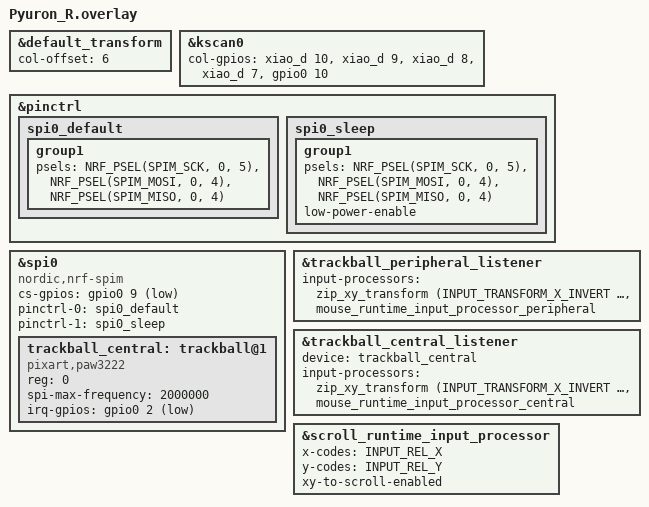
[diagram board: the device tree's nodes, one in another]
#include "Pyuron.dtsi"
#include <zephyr/dt-bindings/input/input-event-codes.h>
#include <dt-bindings/zmk/input_transform.h>
#include <input/processors.dtsi>
#include <input/processors/runtime-input-processor.dtsi>
#include <dt-bindings/zmk/bt.h>

&default_transform {
    col-offset = <6>;
};

&kscan0 {
    col-gpios = <&xiao_d 10 GPIO_ACTIVE_HIGH>,
                <&xiao_d 9 GPIO_ACTIVE_HIGH>,
                <&xiao_d 8 GPIO_ACTIVE_HIGH>,
                <&xiao_d 7 GPIO_ACTIVE_HIGH>,
                <&gpio0 10 GPIO_ACTIVE_HIGH>;
};

&pinctrl {
    spi0_default: spi0_default {
        group1 {
            psels = <NRF_PSEL(SPIM_SCK, 0, 5)>,
                    <NRF_PSEL(SPIM_MOSI, 0, 4)>,
                    <NRF_PSEL(SPIM_MISO, 0, 4)>;
        };
    };

    spi0_sleep: spi0_sleep {
        group1 {
            psels = <NRF_PSEL(SPIM_SCK, 0, 5)>,
                    <NRF_PSEL(SPIM_MOSI, 0, 4)>,
                    <NRF_PSEL(SPIM_MISO, 0, 4)>;
            low-power-enable;
        };
    };
};

&spi0 {
    status = "okay";
    cs-gpios = <&gpio0 9 GPIO_ACTIVE_LOW>;
    pinctrl-0 = <&spi0_default>;
    pinctrl-1 = <&spi0_sleep>;
    pinctrl-names = "default", "sleep";
    compatible = "nordic,nrf-spim";

    trackball_central: trackball@1 {
        status = "okay";
        compatible = "pixart,paw3222";
        reg = <0>;
        spi-max-frequency = <2000000>;
        irq-gpios = <&gpio0 2 (GPIO_ACTIVE_LOW | GPIO_PULL_UP)>;
    };
};

// ペリフェラル（split経由）のリスナーを有効化
&trackball_peripheral_listener {
    status = "okay";
    input-processors = <&zip_xy_transform (INPUT_TRANSFORM_X_INVERT | INPUT_TRANSFORM_Y_INVERT) &mouse_runtime_input_processor_peripheral>;  
    // input-processors = 
    //         <&zip_xy_transform INPUT_TRANSFORM_Y_INVERT>,
    //         <&mouse_runtime_input_processor>,
    //         <&scroll_runtime_input_processor>;
};

// セントラルのリスナーを有効化し、deviceを紐付け
&trackball_central_listener {
    status = "okay";
    device = <&trackball_central>;
    input-processors = 
        <&zip_xy_transform (INPUT_TRANSFORM_X_INVERT | INPUT_TRANSFORM_Y_INVERT) 
         &mouse_runtime_input_processor_central>;
};

&scroll_runtime_input_processor {
        x-codes = <INPUT_REL_X>;
		y-codes = <INPUT_REL_Y>;
		xy-to-scroll-enabled;
};
